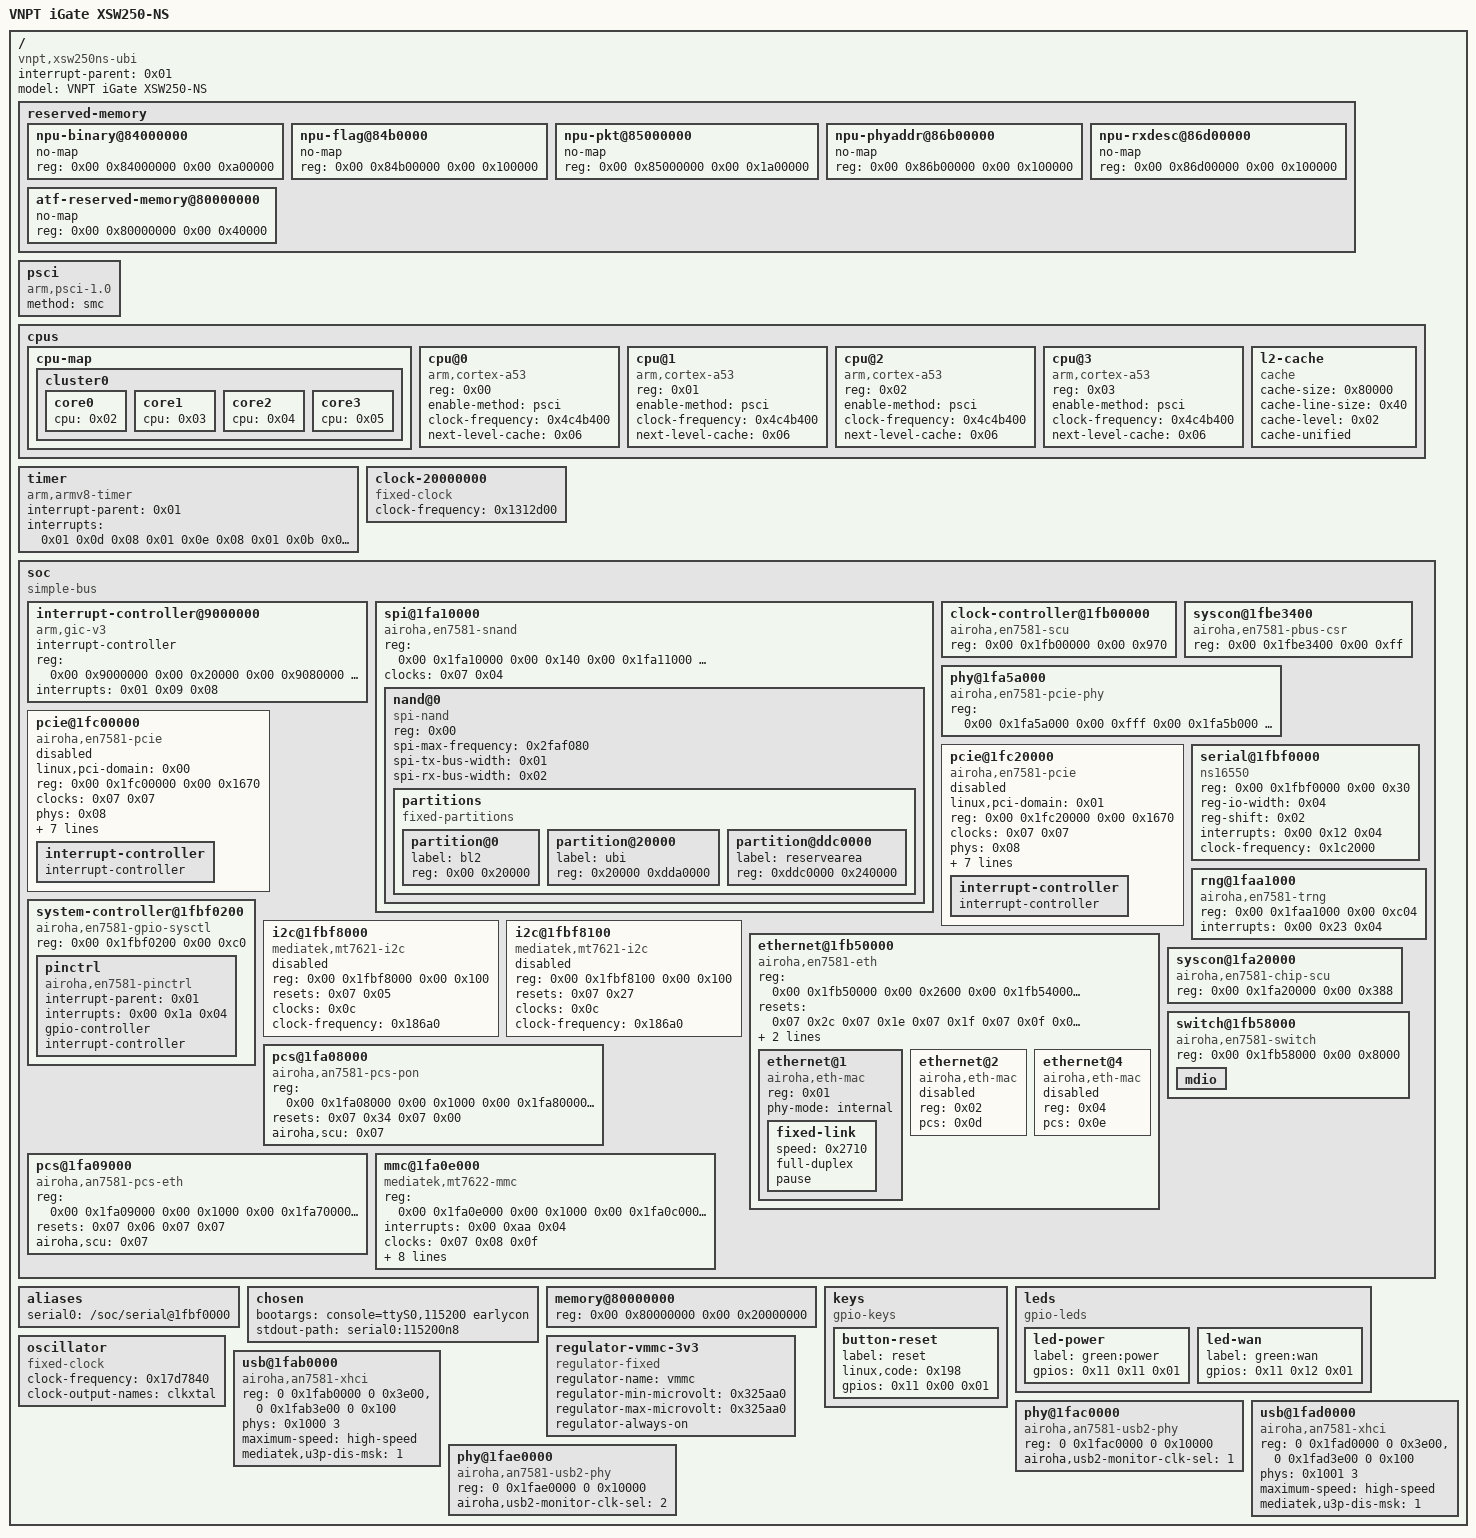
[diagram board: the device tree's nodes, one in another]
/dts-v1/;

/ {
	interrupt-parent = <0x01>;
	#address-cells = <0x02>;
	#size-cells = <0x02>;
	model = "VNPT iGate XSW250-NS";
	compatible = "vnpt,xsw250ns-ubi", "airoha,an7581", "airoha,en7581";

	reserved-memory {
		#address-cells = <0x02>;
		#size-cells = <0x02>;
		ranges;

		npu-binary@84000000 {
			no-map;
			reg = <0x00 0x84000000 0x00 0xa00000>;
		};

		npu-flag@84b0000 {
			no-map;
			reg = <0x00 0x84b00000 0x00 0x100000>;
		};

		npu-pkt@85000000 {
			no-map;
			reg = <0x00 0x85000000 0x00 0x1a00000>;
		};

		npu-phyaddr@86b00000 {
			no-map;
			reg = <0x00 0x86b00000 0x00 0x100000>;
		};

		npu-rxdesc@86d00000 {
			no-map;
			reg = <0x00 0x86d00000 0x00 0x100000>;
		};

		atf-reserved-memory@80000000 {
			no-map;
			reg = <0x00 0x80000000 0x00 0x40000>;
		};
	};

	psci {
		compatible = "arm,psci-1.0";
		method = "smc";
	};

	cpus {
		#address-cells = <0x01>;
		#size-cells = <0x00>;

		cpu-map {

			cluster0 {

				core0 {
					cpu = <0x02>;
				};

				core1 {
					cpu = <0x03>;
				};

				core2 {
					cpu = <0x04>;
				};

				core3 {
					cpu = <0x05>;
				};
			};
		};

		cpu@0 {
			device_type = "cpu";
			compatible = "arm,cortex-a53";
			reg = <0x00>;
			enable-method = "psci";
			clock-frequency = <0x4c4b400>;
			next-level-cache = <0x06>;
			phandle = <0x02>;
		};

		cpu@1 {
			device_type = "cpu";
			compatible = "arm,cortex-a53";
			reg = <0x01>;
			enable-method = "psci";
			clock-frequency = <0x4c4b400>;
			next-level-cache = <0x06>;
			phandle = <0x03>;
		};

		cpu@2 {
			device_type = "cpu";
			compatible = "arm,cortex-a53";
			reg = <0x02>;
			enable-method = "psci";
			clock-frequency = <0x4c4b400>;
			next-level-cache = <0x06>;
			phandle = <0x04>;
		};

		cpu@3 {
			device_type = "cpu";
			compatible = "arm,cortex-a53";
			reg = <0x03>;
			enable-method = "psci";
			clock-frequency = <0x4c4b400>;
			next-level-cache = <0x06>;
			phandle = <0x05>;
		};

		l2-cache {
			compatible = "cache";
			cache-size = <0x80000>;
			cache-line-size = <0x40>;
			cache-level = <0x02>;
			cache-unified;
			phandle = <0x06>;
		};
	};

	timer {
		compatible = "arm,armv8-timer";
		interrupt-parent = <0x01>;
		interrupts = <0x01 0x0d 0x08 0x01 0x0e 0x08 0x01 0x0b 0x08 0x01 0x0a 0x08>;
	};

	clock-20000000 {
		compatible = "fixed-clock";
		#clock-cells = <0x00>;
		clock-frequency = <0x1312d00>;
		phandle = <0x0c>;
	};

	soc {
		compatible = "simple-bus";
		#address-cells = <0x02>;
		#size-cells = <0x02>;
		ranges;

		interrupt-controller@9000000 {
			compatible = "arm,gic-v3";
			interrupt-controller;
			#interrupt-cells = <0x03>;
			#address-cells = <0x01>;
			#size-cells = <0x01>;
			reg = <0x00 0x9000000 0x00 0x20000 0x00 0x9080000 0x00 0x80000 0x00 0x9400000 0x00 0x2000 0x00 0x9500000 0x00 0x2000 0x00 0x9600000 0x00 0x20000>;
			interrupts = <0x01 0x09 0x08>;
			phandle = <0x01>;
		};

		spi@1fa10000 {
			compatible = "airoha,en7581-snand";
			reg = <0x00 0x1fa10000 0x00 0x140 0x00 0x1fa11000 0x00 0x600>;
			clocks = <0x07 0x04>;
			clock-names = "spi";
			#address-cells = <0x01>;
			#size-cells = <0x00>;
			status = "okay";

			nand@0 {
				compatible = "spi-nand";
				reg = <0x00>;
				spi-max-frequency = <0x2faf080>;
				spi-tx-bus-width = <0x01>;
				spi-rx-bus-width = <0x02>;

				partitions {
					compatible = "fixed-partitions";
					#address-cells = <0x01>;
					#size-cells = <0x01>;

					partition@0 {
						label = "bl2";
						reg = <0x00 0x20000>;
					};

					partition@20000 {
						label = "ubi";
						reg = <0x20000 0xdda0000>;
					};

					partition@ddc0000 {
						label = "reservearea";
						reg = <0xddc0000 0x240000>;
					};
				};
			};
		};

		clock-controller@1fb00000 {
			compatible = "airoha,en7581-scu", "syscon";
			reg = <0x00 0x1fb00000 0x00 0x970>;
			#clock-cells = <0x01>;
			#reset-cells = <0x01>;
			phandle = <0x07>;
		};

		syscon@1fbe3400 {
			compatible = "airoha,en7581-pbus-csr", "syscon";
			reg = <0x00 0x1fbe3400 0x00 0xff>;
			phandle = <0x09>;
		};

		phy@1fa5a000 {
			compatible = "airoha,en7581-pcie-phy";
			reg = <0x00 0x1fa5a000 0x00 0xfff 0x00 0x1fa5b000 0x00 0xfff 0x00 0x1fa5c000 0x00 0xfff 0x00 0x1fc10044 0x00 0x04 0x00 0x1fc30044 0x00 0x04 0x00 0x1fc15030 0x00 0x104>;
			reg-names = "csr-2l", "pma0", "pma1", "p0-xr-dtime", "p1-xr-dtime", "rx-aeq";
			#phy-cells = <0x00>;
			phandle = <0x08>;
		};

		pcie@1fc00000 {
			compatible = "airoha,en7581-pcie";
			device_type = "pci";
			linux,pci-domain = <0x00>;
			#address-cells = <0x03>;
			#size-cells = <0x02>;
			reg = <0x00 0x1fc00000 0x00 0x1670>;
			reg-names = "pcie-mac";
			clocks = <0x07 0x07>;
			clock-names = "sys-ck";
			phys = <0x08>;
			phy-names = "pcie-phy";
			ranges = <0x2000000 0x00 0x20000000 0x00 0x20000000 0x00 0x4000000>;
			resets = <0x07 0x30 0x07 0x31 0x07 0x19>;
			reset-names = "phy-lane0", "phy-lane1", "phy-lane2";
			mediatek,pbus-csr = <0x09 0x00 0x04>;
			interrupts = <0x00 0x27 0x04>;
			bus-range = <0x00 0xff>;
			#interrupt-cells = <0x01>;
			interrupt-map-mask = <0x00 0x00 0x00 0x07>;
			interrupt-map = <0x00 0x00 0x00 0x01 0x0a 0x00 0x00 0x00 0x00 0x02 0x0a 0x01 0x00 0x00 0x00 0x03 0x0a 0x02 0x00 0x00 0x00 0x04 0x0a 0x03>;
			status = "disabled";

			interrupt-controller {
				interrupt-controller;
				#address-cells = <0x00>;
				#interrupt-cells = <0x01>;
				phandle = <0x0a>;
			};
		};

		pcie@1fc20000 {
			compatible = "airoha,en7581-pcie";
			device_type = "pci";
			linux,pci-domain = <0x01>;
			#address-cells = <0x03>;
			#size-cells = <0x02>;
			reg = <0x00 0x1fc20000 0x00 0x1670>;
			reg-names = "pcie-mac";
			clocks = <0x07 0x07>;
			clock-names = "sys-ck";
			phys = <0x08>;
			phy-names = "pcie-phy";
			ranges = <0x2000000 0x00 0x24000000 0x00 0x24000000 0x00 0x4000000>;
			resets = <0x07 0x30 0x07 0x31 0x07 0x19>;
			reset-names = "phy-lane0", "phy-lane1", "phy-lane2";
			mediatek,pbus-csr = <0x09 0x08 0x0c>;
			interrupts = <0x00 0x28 0x04>;
			bus-range = <0x00 0xff>;
			#interrupt-cells = <0x01>;
			interrupt-map-mask = <0x00 0x00 0x00 0x07>;
			interrupt-map = <0x00 0x00 0x00 0x01 0x0b 0x00 0x00 0x00 0x00 0x02 0x0b 0x01 0x00 0x00 0x00 0x03 0x0b 0x02 0x00 0x00 0x00 0x04 0x0b 0x03>;
			status = "disabled";

			interrupt-controller {
				interrupt-controller;
				#address-cells = <0x00>;
				#interrupt-cells = <0x01>;
				phandle = <0x0b>;
			};
		};

		serial@1fbf0000 {
			compatible = "ns16550";
			reg = <0x00 0x1fbf0000 0x00 0x30>;
			reg-io-width = <0x04>;
			reg-shift = <0x02>;
			interrupts = <0x00 0x12 0x04>;
			clock-frequency = <0x1c2000>;
			bootph-all;
		};

		rng@1faa1000 {
			compatible = "airoha,en7581-trng";
			reg = <0x00 0x1faa1000 0x00 0xc04>;
			interrupts = <0x00 0x23 0x04>;
		};

		system-controller@1fbf0200 {
			compatible = "airoha,en7581-gpio-sysctl", "syscon", "simple-mfd";
			reg = <0x00 0x1fbf0200 0x00 0xc0>;

			pinctrl {
				compatible = "airoha,en7581-pinctrl";
				interrupt-parent = <0x01>;
				interrupts = <0x00 0x1a 0x04>;
				gpio-controller;
				#gpio-cells = <0x02>;
				interrupt-controller;
				#interrupt-cells = <0x02>;
				phandle = <0x11>;
			};
		};

		i2c@1fbf8000 {
			compatible = "mediatek,mt7621-i2c";
			reg = <0x00 0x1fbf8000 0x00 0x100>;
			resets = <0x07 0x05>;
			clocks = <0x0c>;
			clock-frequency = <0x186a0>;
			#address-cells = <0x01>;
			#size-cells = <0x00>;
			status = "disabled";
		};

		i2c@1fbf8100 {
			compatible = "mediatek,mt7621-i2c";
			reg = <0x00 0x1fbf8100 0x00 0x100>;
			resets = <0x07 0x27>;
			clocks = <0x0c>;
			clock-frequency = <0x186a0>;
			#address-cells = <0x01>;
			#size-cells = <0x00>;
			status = "disabled";
		};

		ethernet@1fb50000 {
			compatible = "airoha,en7581-eth";
			reg = <0x00 0x1fb50000 0x00 0x2600 0x00 0x1fb54000 0x00 0x2000 0x00 0x1fb56000 0x00 0x2000>;
			reg-names = "fe", "qdma0", "qdma1";
			resets = <0x07 0x2c 0x07 0x1e 0x07 0x1f 0x07 0x0f 0x07 0x10 0x07 0x11 0x07 0x1a>;
			reset-names = "fe", "pdma", "qdma", "hsi0-mac", "hsi1-mac", "hsi-mac", "xfp-mac";
			interrupts = <0x00 0x25 0x04 0x00 0x37 0x04 0x00 0x38 0x04 0x00 0x39 0x04 0x00 0x26 0x04 0x00 0x3a 0x04 0x00 0x3b 0x04 0x00 0x3c 0x04 0x00 0x31 0x04 0x00 0x40 0x04>;
			status = "okay";
			#address-cells = <0x01>;
			#size-cells = <0x00>;

			ethernet@1 {
				compatible = "airoha,eth-mac";
				reg = <0x01>;
				phy-mode = "internal";
				status = "okay";

				fixed-link {
					speed = <0x2710>;
					full-duplex;
					pause;
				};
			};

			ethernet@2 {
				compatible = "airoha,eth-mac";
				reg = <0x02>;
				pcs = <0x0d>;
				status = "disabled";
			};

			ethernet@4 {
				compatible = "airoha,eth-mac";
				reg = <0x04>;
				pcs = <0x0e>;
				status = "disabled";
			};
		};

		syscon@1fa20000 {
			compatible = "airoha,en7581-chip-scu", "syscon";
			reg = <0x00 0x1fa20000 0x00 0x388>;
		};

		pcs@1fa08000 {
			compatible = "airoha,an7581-pcs-pon";
			reg = <0x00 0x1fa08000 0x00 0x1000 0x00 0x1fa80000 0x00 0x60 0x00 0x1fa80a00 0x00 0x164 0x00 0x1fa84000 0x00 0x450 0x00 0x1fa85900 0x00 0x338 0x00 0x1fa86000 0x00 0x300 0x00 0x1fa8a000 0x00 0x1000 0x00 0x1fa8b000 0x00 0x1000>;
			reg-names = "xfi_mac", "hsgmii_an", "hsgmii_pcs", "multi_sgmii", "usxgmii", "hsgmii_rate_adp", "xfi_ana", "xfi_pma";
			resets = <0x07 0x34 0x07 0x00>;
			reset-names = "mac", "phy";
			airoha,scu = <0x07>;
			phandle = <0x0d>;
		};

		pcs@1fa09000 {
			compatible = "airoha,an7581-pcs-eth";
			reg = <0x00 0x1fa09000 0x00 0x1000 0x00 0x1fa70000 0x00 0x60 0x00 0x1fa70a00 0x00 0x164 0x00 0x1fa74000 0x00 0x450 0x00 0x1fa75900 0x00 0x338 0x00 0x1fa76000 0x00 0x300 0x00 0x1fa7a000 0x00 0x1000 0x00 0x1fa7b000 0x00 0x1000>;
			reg-names = "xfi_mac", "hsgmii_an", "hsgmii_pcs", "multi_sgmii", "usxgmii", "hsgmii_rate_adp", "xfi_ana", "xfi_pma";
			resets = <0x07 0x06 0x07 0x07>;
			reset-names = "mac", "phy";
			airoha,scu = <0x07>;
			phandle = <0x0e>;
		};

		switch@1fb58000 {
			compatible = "airoha,en7581-switch";
			reg = <0x00 0x1fb58000 0x00 0x8000>;

			mdio {
				#address-cells = <0x01>;
				#size-cells = <0x00>;
			};
		};

		mmc@1fa0e000 {
			compatible = "mediatek,mt7622-mmc";
			reg = <0x00 0x1fa0e000 0x00 0x1000 0x00 0x1fa0c000 0x00 0x60>;
			interrupts = <0x00 0xaa 0x04>;
			clocks = <0x07 0x08 0x0f>;
			clock-names = "source", "hclk";
			bus-width = <0x04>;
			max-frequency = <0x3197500>;
			vmmc-supply = <0x10>;
			disable-wp;
			cap-mmc-highspeed;
			non-removable;
			assigned-clocks = <0x07 0x08>;
			assigned-clock-rates = <0xbebc200>;
		};
	};

	aliases {
		serial0 = "/soc/serial@1fbf0000";
	};

	chosen {
		bootargs = "console=ttyS0,115200 earlycon";
		stdout-path = "serial0:115200n8";
	};

	memory@80000000 {
		device_type = "memory";
		reg = <0x00 0x80000000 0x00 0x20000000>;
	};

	keys {
		compatible = "gpio-keys";

		button-reset {
			label = "reset";
			linux,code = <0x198>;
			gpios = <0x11 0x00 0x01>;
		};
	};

	leds {
		compatible = "gpio-leds";

		led-power {
			label = "green:power";
			gpios = <0x11 0x11 0x01>;
		};

		led-wan {
			label = "green:wan";
			gpios = <0x11 0x12 0x01>;
		};
	};

	oscillator {
		compatible = "fixed-clock";
		#clock-cells = <0x00>;
		clock-frequency = <0x17d7840>;
		clock-output-names = "clkxtal";
		phandle = <0x0f>;
	};

	regulator-vmmc-3v3 {
		compatible = "regulator-fixed";
		regulator-name = "vmmc";
		regulator-min-microvolt = <0x325aa0>;
		regulator-max-microvolt = <0x325aa0>;
		regulator-always-on;
		phandle = <0x10>;
	};

	/* USB2-only host ports; external mod supplies VBUS. No SerDes switch. */
	usb@1fab0000 {
        compatible = "airoha,an7581-xhci", "mediatek,mtk-xhci";
        reg = <0 0x1fab0000 0 0x3e00>, <0 0x1fab3e00 0 0x100>;
        reg-names = "mac", "ippc";
        phys = <0x1000 3>;
        maximum-speed = "high-speed";
        mediatek,u3p-dis-msk = <1>;
        status = "okay";
    };
    phy@1fac0000 {
        compatible = "airoha,an7581-usb2-phy";
        reg = <0 0x1fac0000 0 0x10000>;
        #phy-cells = <1>;
        airoha,usb2-monitor-clk-sel = <1>;
        phandle = <0x1000>;
    };
	usb@1fad0000 {
        compatible = "airoha,an7581-xhci", "mediatek,mtk-xhci";
        reg = <0 0x1fad0000 0 0x3e00>, <0 0x1fad3e00 0 0x100>;
        reg-names = "mac", "ippc";
        phys = <0x1001 3>;
        maximum-speed = "high-speed";
        mediatek,u3p-dis-msk = <1>;
        status = "okay";
    };
    phy@1fae0000 {
        compatible = "airoha,an7581-usb2-phy";
        reg = <0 0x1fae0000 0 0x10000>;
        #phy-cells = <1>;
        airoha,usb2-monitor-clk-sel = <2>;
        phandle = <0x1001>;
    };
};
